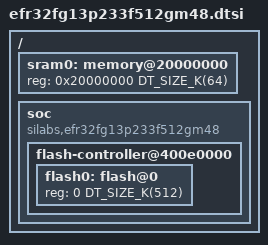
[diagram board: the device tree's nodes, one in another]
/*
 * Copyright (c) 2018 Linaro Limited
 * Copyright (c) 2021 Yonatan Schachter
 *
 * SPDX-License-Identifier: Apache-2.0
 */

#include <mem.h>
#include <silabs/efr32xg13p.dtsi>

/ {
	sram0: memory@20000000 {
		reg = <0x20000000 DT_SIZE_K(64)>;
	};

	soc {
		compatible = "silabs,efr32fg13p233f512gm48", "silabs,efr32xg13p",
					 "silabs,efr32", "simple-bus";

		flash-controller@400e0000 {
			flash0: flash@0 {
				reg = <0 DT_SIZE_K(512)>;
			};
		};
	};
};
